VERSION ""

NS_ :

BS_:

BU_: EON PED IBST EPAS GAS_ACTUATOR BRAKE_ACTUATOR STEER_ACTUATOR

VAL_TABLE_ BRAKEMODE 3 "Reserved" 2 "Position Control" 1 "Relative Control" 0 "Disengadged" ;
VAL_TABLE_ STATUS 5 "FAULT_TIMEOUT" 4 "FAULT_STARTUP" 3 "FAULT_SCE" 2 "FAULT_SEND" 1 "FAULT_BAD_CHECKSUM" 0 "NO_FAULT" ;
VAL_TABLE_ YESNO 1 "Yes" 0 "No" ;

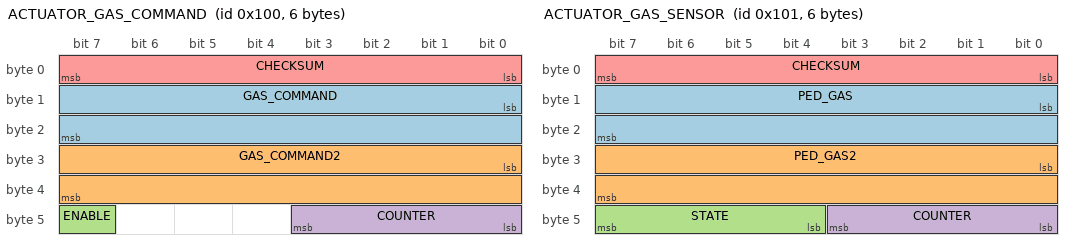
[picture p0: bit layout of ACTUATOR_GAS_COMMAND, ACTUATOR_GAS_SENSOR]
BO_ 256 ACTUATOR_GAS_COMMAND: 6 EON
 SG_ GAS_COMMAND : 8|16@1+ (0.275676,-33.3567) [0|1] ""  GAS_ACTUATOR
 SG_ GAS_COMMAND2 : 24|16@1+ (0.13629,-32.71) [0|1] ""  GAS_ACTUATOR
 SG_ ENABLE : 47|1@1+ (1,0) [0|1] ""  GAS_ACTUATOR
 SG_ COUNTER : 40|4@1+ (1,0) [0|15] ""  GAS_ACTUATOR
 SG_ CHECKSUM : 0|8@1+ (1,0) [0|255] ""  GAS_ACTUATOR

BO_ 257 ACTUATOR_GAS_SENSOR: 6 GAS_ACTUATOR
 SG_ PED_GAS : 8|16@1+ (0.275676,-33.3567) [0|1] ""  EON
 SG_ PED_GAS2 : 24|16@1+ (0.13629,-32.71) [0|1] ""  EON
 SG_ STATE : 44|4@1+ (1,0) [0|15] ""  EON
 SG_ COUNTER : 40|4@1+ (1,0) [0|15] ""  EON
 SG_ CHECKSUM : 0|8@1+ (1,0) [0|255] ""  EON

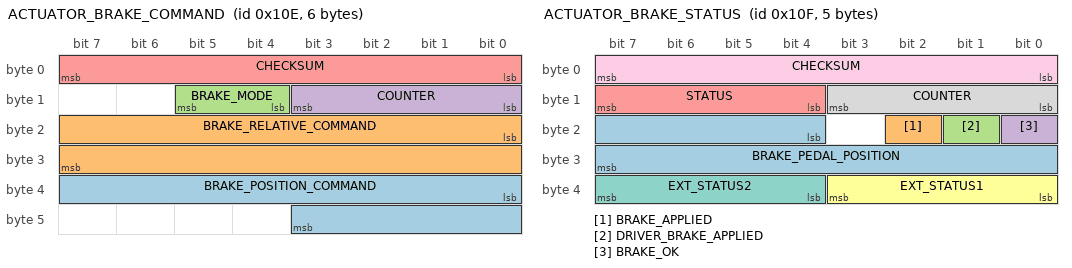
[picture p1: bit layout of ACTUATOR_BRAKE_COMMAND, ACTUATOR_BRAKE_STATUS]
BO_ 270 ACTUATOR_BRAKE_COMMAND: 6 EON
 SG_ BRAKE_POSITION_COMMAND : 32|12@1+ (0.015625,-5) [-5|47] "mm" BRAKE_ACTUATOR
 SG_ BRAKE_RELATIVE_COMMAND : 16|16@1+ (0.0078125,-252) [-252|252] "" BRAKE_ACTUATOR
 SG_ BRAKE_MODE : 12|2@1+ (1,0) [0|3] "" BRAKE_ACTUATOR
 SG_ COUNTER : 8|4@1+ (1,0) [0|15] "" BRAKE_ACTUATOR
 SG_ CHECKSUM : 0|8@1+ (1,0) [0|255] "" BRAKE_ACTUATOR

BO_ 271 ACTUATOR_BRAKE_STATUS: 5 BRAKE_ACTUATOR
 SG_ BRAKE_PEDAL_POSITION : 20|12@1+ (0.015625,-5) [-5|47] "mm" EON
 SG_ BRAKE_APPLIED : 18|1@1+ (1,0) [0|1] "" EON
 SG_ DRIVER_BRAKE_APPLIED : 17|1@1+ (1,0) [0|1] "" EON
 SG_ BRAKE_OK : 16|1@1+ (1,0) [0|1] "" EON
 SG_ STATUS : 12|4@1+ (1,0) [0|15] "" EON
 SG_ EXT_STATUS1 : 32|4@1+ (1,0) [0|15] "" EON
 SG_ EXT_STATUS2 : 36|4@1+ (1,0) [0|15] "" EON
 SG_ COUNTER : 8|4@1+ (1,0) [0|15] "" EON
 SG_ CHECKSUM : 0|8@1+ (1,0) [0|255] "" EON

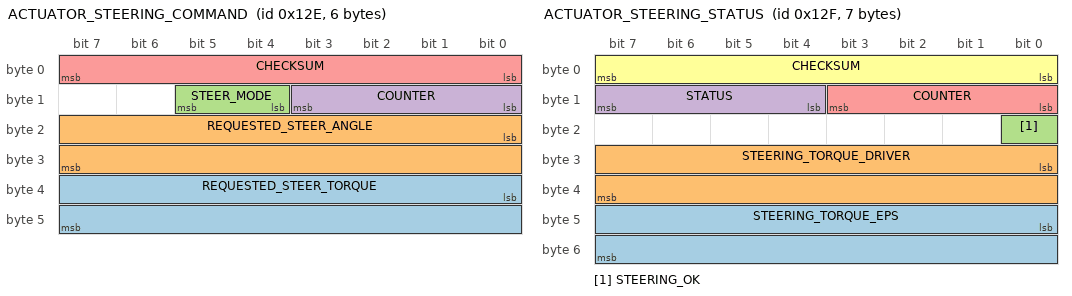
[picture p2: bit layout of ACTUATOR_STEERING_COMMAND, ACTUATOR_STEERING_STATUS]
BO_ 302 ACTUATOR_STEERING_COMMAND: 6 EON
 SG_ REQUESTED_STEER_TORQUE : 32|16@1- (0.5,0) [-512|511.5] "Nm" STEER_ACTUATOR
 SG_ REQUESTED_STEER_ANGLE : 16|16@1- (0.1,0) [-1638.4|1638.3] "deg" STEER_ACTUATOR
 SG_ STEER_MODE : 12|2@1+ (1,0) [0|3] "" STEER_ACTUATOR
 SG_ COUNTER : 8|4@1+ (1,0) [0|15] "" STEER_ACTUATOR
 SG_ CHECKSUM : 0|8@1+ (1,0) [0|255] "" STEER_ACTUATOR

BO_ 303 ACTUATOR_STEERING_STATUS: 7 STEER_ACTUATOR
 SG_ STEERING_TORQUE_EPS : 40|16@1- (0.8,0) [-819.2|818.4] "Nm" EON
 SG_ STEERING_TORQUE_DRIVER : 24|16@1- (0.8,0) [-819.2|818.4] "Nm" EON
 SG_ STEERING_OK : 16|1@1+ (1,0) [0|1] "" EON
 SG_ STATUS : 12|4@1+ (1,0) [0|15] "" EON
 SG_ COUNTER : 8|4@1+ (1,0) [0|15] "" EON
 SG_ CHECKSUM : 0|8@1+ (1,0) [0|255] "" EON

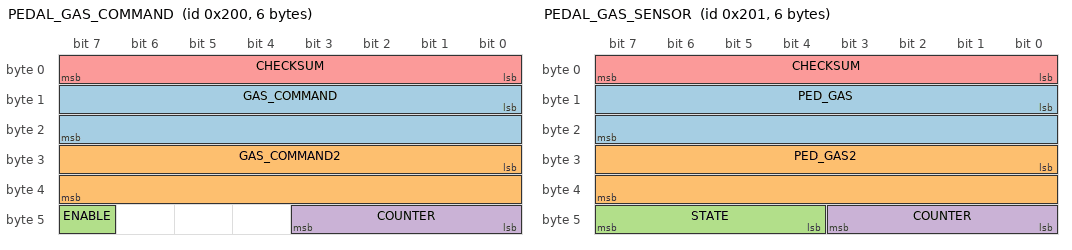
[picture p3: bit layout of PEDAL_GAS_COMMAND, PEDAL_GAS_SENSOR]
BO_ 512 PEDAL_GAS_COMMAND: 6 EON
 SG_ GAS_COMMAND : 8|16@1+ (0.275676,-33.3567) [0|1] ""  PED
 SG_ GAS_COMMAND2 : 24|16@1+ (0.13629,-32.71) [0|1] ""  PED
 SG_ ENABLE : 47|1@1+ (1,0) [0|1] ""  PED
 SG_ COUNTER : 40|4@1+ (1,0) [0|15] ""  PED
 SG_ CHECKSUM : 0|8@1+ (1,0) [0|255] ""  PED

BO_ 513 PEDAL_GAS_SENSOR: 6 PED
 SG_ PED_GAS : 8|16@1+ (0.275676,-33.3567) [0|1] ""  EON
 SG_ PED_GAS2 : 24|16@1+ (0.13629,-32.71) [0|1] ""  EON
 SG_ STATE : 44|4@1+ (1,0) [0|15] ""  EON
 SG_ COUNTER : 40|4@1+ (1,0) [0|15] ""  EON
 SG_ CHECKSUM : 0|8@1+ (1,0) [0|255] ""  EON

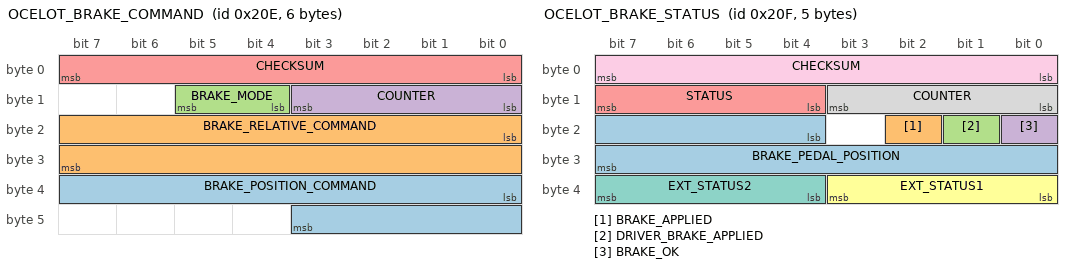
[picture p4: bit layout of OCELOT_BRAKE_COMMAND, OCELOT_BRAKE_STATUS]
BO_ 526 OCELOT_BRAKE_COMMAND: 6 EON
 SG_ BRAKE_POSITION_COMMAND : 32|12@1+ (0.015625,-5) [-5|47] "mm" IBST
 SG_ BRAKE_RELATIVE_COMMAND : 16|16@1+ (0.0078125,-252) [-252|252] "" IBST
 SG_ BRAKE_MODE : 12|2@1+ (1,0) [0|3] "" IBST
 SG_ COUNTER : 8|4@1+ (1,0) [0|15] "" IBST
 SG_ CHECKSUM : 0|8@1+ (1,0) [0|255] "" IBST

BO_ 527 OCELOT_BRAKE_STATUS: 5 IBST
 SG_ BRAKE_PEDAL_POSITION : 20|12@1+ (0.015625,-5) [-5|47] "mm" EON
 SG_ BRAKE_APPLIED : 18|1@1+ (1,0) [0|1] "" EON
 SG_ DRIVER_BRAKE_APPLIED : 17|1@1+ (1,0) [0|1] "" EON
 SG_ BRAKE_OK : 16|1@1+ (1,0) [0|1] "" EON
 SG_ STATUS : 12|4@1+ (1,0) [0|15] "" EON
 SG_ EXT_STATUS1 : 32|4@1+ (1,0) [0|15] "" EON
 SG_ EXT_STATUS2 : 36|4@1+ (1,0) [0|15] "" EON
 SG_ COUNTER : 8|4@1+ (1,0) [0|15] "" EON
 SG_ CHECKSUM : 0|8@1+ (1,0) [0|255] "" EON

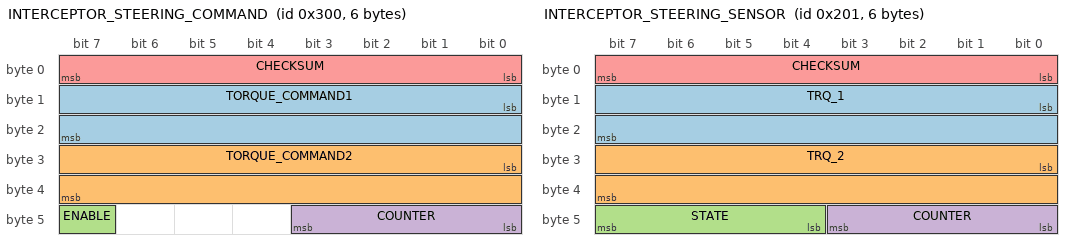
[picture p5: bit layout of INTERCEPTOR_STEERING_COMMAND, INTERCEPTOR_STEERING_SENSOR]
BO_ 768 INTERCEPTOR_STEERING_COMMAND: 6 EON
 SG_ TORQUE_COMMAND1 : 8|16@1- (1,0) [0|1] ""  PED
 SG_ TORQUE_COMMAND2 : 24|16@1- (1,0) [0|1] ""  PED
 SG_ ENABLE : 47|1@1+ (1,0) [0|1] ""  PED
 SG_ COUNTER : 40|4@1+ (1,0) [0|15] ""  PED
 SG_ CHECKSUM : 0|8@1+ (1,0) [0|255] ""  PED

BO_ 513 INTERCEPTOR_STEERING_SENSOR: 6 PED
 SG_ TRQ_1 : 8|16@1+ (0.275676,-33.3567) [0|1] ""  EON
 SG_ TRQ_2 : 24|16@1+ (0.13629,-32.71) [0|1] ""  EON
 SG_ STATE : 44|4@1+ (1,0) [0|15] ""  EON
 SG_ COUNTER : 40|4@1+ (1,0) [0|15] ""  EON
 SG_ CHECKSUM : 0|8@1+ (1,0) [0|255] ""  EON

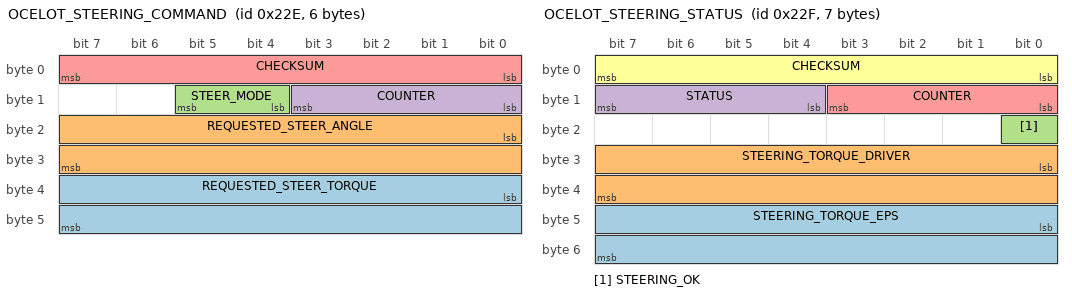
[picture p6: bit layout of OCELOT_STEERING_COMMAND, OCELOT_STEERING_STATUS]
BO_ 558 OCELOT_STEERING_COMMAND: 6 EON
 SG_ REQUESTED_STEER_TORQUE : 32|16@1- (1,0) [-1500|1500] "Nm" EPAS
 SG_ REQUESTED_STEER_ANGLE : 16|16@1- (0.1,0) [-1638.4|1638.3] "deg" EPAS
 SG_ STEER_MODE : 12|2@1+ (1,0) [0|3] "" EPAS
 SG_ COUNTER : 8|4@1+ (1,0) [0|15] "" EPAS
 SG_ CHECKSUM : 0|8@1+ (1,0) [0|255] "" EPAS

BO_ 559 OCELOT_STEERING_STATUS: 7 EPAS
 SG_ STEERING_TORQUE_EPS : 40|16@1- (0.8,0) [-819.2|818.4] "Nm" EON
 SG_ STEERING_TORQUE_DRIVER : 24|16@1- (0.8,0) [-819.2|818.4] "Nm" EON
 SG_ STEERING_OK : 16|1@1+ (1,0) [0|1] "" EON
 SG_ STATUS : 12|4@1+ (1,0) [0|15] "" EON
 SG_ COUNTER : 8|4@1+ (1,0) [0|15] "" EON
 SG_ CHECKSUM : 0|8@1+ (1,0) [0|255] "" EON

 VAL_ 527 IBOOSTER_BRAKE_APPLIED 1 "Yes" 0 "No" ;
 VAL_ 527 BRAKE_OK 1 "Yes" 0 "No" ;
 VAL_ 527 STATUS 5 "FAULT_TIMEOUT" 4 "FAULT_STARTUP" 3 "FAULT_SCE" 2 "FAULT_SEND" 1 "FAULT_BAD_CHECKSUM" 0 "NO_FAULT" ;
 VAL_ 526 BRAKE_MODE 3 "Reserved" 2 "Position Control" 1 "Relative Control" 0 "Disengadged" ;
